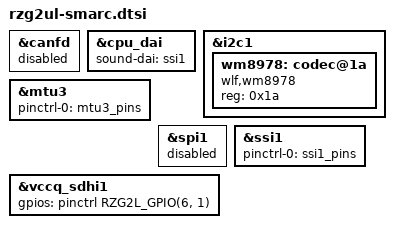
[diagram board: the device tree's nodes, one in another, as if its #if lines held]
#include "rzg2ul-smarc-pinfunction.dtsi"
#include "rz-smarc-common.dtsi"
#if (!SW_ET0_EN_N)
&canfd {
	/delete-property/ pinctrl-0;
	/delete-property/ pinctrl-names;
	status = "disabled";
};
#endif
&cpu_dai {
	sound-dai = <&ssi1>;
};
&i2c1 {
	wm8978: codec@1a {
		compatible = "wlf,wm8978";
		#sound-dai-cells = <0>;
		reg = <0x1a>;
	};
};
#if PMOD_MTU3
&mtu3 {
	pinctrl-0 = <&mtu3_pins>;
	pinctrl-names = "default";
	status = "okay";
};
&spi1 {
	status = "disabled";
};
#endif
#if (SW_ET0_EN_N)
&ssi1 {
	pinctrl-0 = <&ssi1_pins>;
	pinctrl-names = "default";
	status = "okay";
};
#else
&snd_rzg2l {
	status = "disabled";
};
&spi1 {
	/delete-property/ pinctrl-0;
	/delete-property/ pinctrl-names;
	status = "disabled";
};
&ssi1 {
	/delete-property/ pinctrl-0;
	/delete-property/ pinctrl-names;
	status = "disabled";
};
#endif
&vccq_sdhi1 {
	gpios = <&pinctrl RZG2L_GPIO(6, 1) GPIO_ACTIVE_HIGH>;
};
